AUTOSAR XML (schema 4-0-3)
standard types defined: uint8, UInt32, UInt8
package /AUTOSAR_Platform/DataConstrs
  range DC_UInt8: raw 0..255
package /PATAC/MSM/ComponentTypes
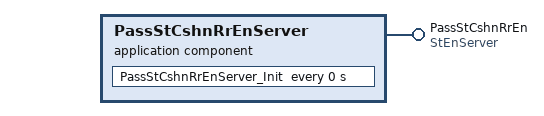
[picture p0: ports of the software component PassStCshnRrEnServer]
  application sw component type PassStCshnRrEnServer
    provide port PassStCshnRrEn: provided-com-specs=[{operation=Clear, queue-length=1}, {operation=Get, queue-length=1}, {operation=Set, queue-length=1}], provided-interface=StEnServer
    behavior PassStCshnRrEnServer_InternalBehavior
      operation invoked event OIT_PassStCshnRrEn_Clear_PassStCshnRrEn_Clear: start-on-event=PassStCshnRrEn_Clear, operation=PassStCshnRrEn.Clear
      operation invoked event OIT_PassStCshnRrEn_Get_PassStCshnRrEn_Get: start-on-event=PassStCshnRrEn_Get, operation=PassStCshnRrEn.Get
      operation invoked event OIT_PassStCshnRrEn_Set_PassStCshnRrEn_Set: start-on-event=PassStCshnRrEn_Set, operation=PassStCshnRrEn.Set
      timing event PassStCshnRrEnServer_InitEvent: start-on-event=PassStCshnRrEnServer_Init, period=0
      4 x runnable:
        PassStCshnRrEn_Clear
        PassStCshnRrEn_Get
        PassStCshnRrEn_Set
        PassStCshnRrEnServer_Init
  swc implementation PassStCshnRrEnServer_Implementation: behavior=PassStCshnRrEnServer_InternalBehavior
    code-descriptors:
      code Default: artifact-descriptors=autosar-engineering-object={short-label=Default, category=SWSRC}
package /PATAC/MSM/ModeAdjust/PortInterface
  client server interface StEnServer
    operation Clear
      arg data: type=UInt8, direction=IN, server-argument-impl-policy=USE-ARGUMENT-TYPE
    operation Get
      arg data: type=UInt32, direction=OUT, server-argument-impl-policy=USE-ARGUMENT-TYPE
    operation Set
      arg data: type=UInt8, direction=IN, server-argument-impl-policy=USE-ARGUMENT-TYPE
